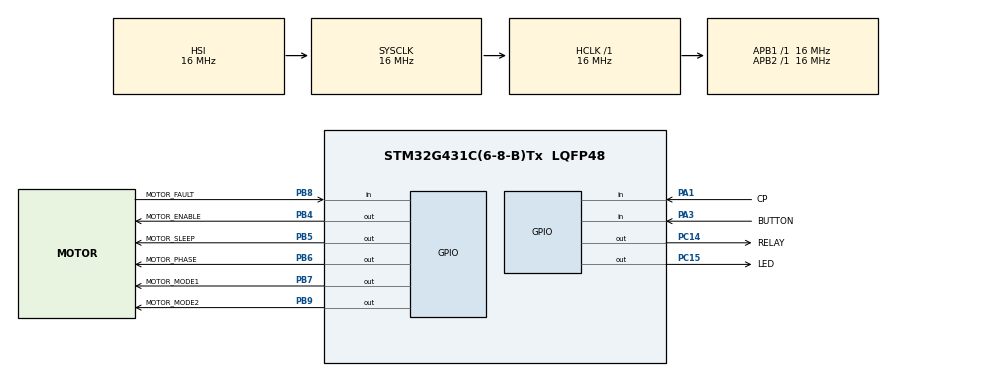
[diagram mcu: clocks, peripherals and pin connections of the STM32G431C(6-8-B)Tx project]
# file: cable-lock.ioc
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Mcu.Family=STM32G4
Mcu.Name=STM32G431C(6-8-B)Tx
Mcu.Package=LQFP48
NVIC.PriorityGroup=NVIC_PRIORITYGROUP_4
PA0.GPIO_Label=CP_WKUP
PA0.Mode=SYS_WakeUp0
PA0.Signal=SYS_WKUP1
PA1.GPIO_Label=CP
PA1.Signal=GPIO_Input
PA13.Mode=Serial_Wire
PA13.Signal=SYS_JTMS-SWDIO
PA14.Mode=Serial_Wire
PA14.Signal=SYS_JTCK-SWCLK
PA2.GPIO_Label=BUTTON_WKUP
PA2.Mode=SYS_WakeUp3
PA2.Signal=SYS_WKUP4
PA3.GPIO_Label=BUTTON
PA3.Signal=GPIO_Input
PB4.GPIO_Label=MOTOR_ENABLE
PB4.Signal=GPIO_Output
PB5.GPIO_Label=MOTOR_SLEEP
PB5.Signal=GPIO_Output
PB6.GPIO_Label=MOTOR_PHASE
PB6.Signal=GPIO_Output
PB7.GPIO_Label=MOTOR_MODE1
PB7.Signal=GPIO_Output
PB8-BOOT0.GPIO_Label=MOTOR_FAULT
PB8-BOOT0.Signal=GPIO_Input
PB9.GPIO_Label=MOTOR_MODE2
PB9.Signal=GPIO_Output
PC14-OSC32_IN.GPIO_Label=RELAY
PC14-OSC32_IN.Signal=GPIO_Output
PC15-OSC32_OUT.GPIO_Label=LED
PC15-OSC32_OUT.Signal=GPIO_Output
ProjectManager.HeapSize=0x200
ProjectManager.StackSize=0x400
ProjectManager.TargetToolchain=Makefile
RCC.AHBFreq_Value=16000000
RCC.APB1Freq_Value=16000000
RCC.APB1TimFreq_Value=16000000
RCC.APB2Freq_Value=16000000
RCC.APB2TimFreq_Value=16000000
RCC.CortexFreq_Value=16000000
RCC.EXTERNAL_CLOCK_VALUE=12288000
RCC.HCLKFreq_Value=16000000
RCC.HSE_VALUE=8000000
RCC.HSI48_VALUE=48000000
RCC.HSI_VALUE=16000000
RCC.LSE_VALUE=32768
RCC.SYSCLKFreq_VALUE=16000000
RCC.USBFreq_Value=64000000
RCC.VCOOutputFreq_Value=128000000
VP_SYS_VS_DBSignals.Mode=DisableDeadBatterySignals
board=custom

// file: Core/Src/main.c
/* USER CODE BEGIN Header */
/**
  ******************************************************************************
  * @file           : main.c
  * @brief          : Main program body
  ******************************************************************************
  * @attention
  *
  * Copyright (c) 2026 STMicroelectronics.
  * All rights reserved.
  *
  * This software is licensed under terms that can be found in the LICENSE file
  * in the root directory of this software component.
  * If no LICENSE file comes with this software, it is provided AS-IS.
  *
  ******************************************************************************
  */
/* USER CODE END Header */
#include "main.h"

/* USER CODE BEGIN Includes */
#include "cable-lock.h"
/* USER CODE END Includes */

void SystemClock_Config(void);
static void MX_GPIO_Init(void);

int main(void)
{

  /* MCU Configuration--------------------------------------------------------*/

  /* Reset of all peripherals, Initializes the Flash interface and the Systick. */
  HAL_Init();

  /* Configure the system clock */
  SystemClock_Config();

  /* Initialize all configured peripherals */
  MX_GPIO_Init();
  /* USER CODE BEGIN 2 */
  cable_lock();
  /* USER CODE END 2 */

  /* Infinite loop */
  while (1)
  {

  }
}

void SystemClock_Config(void)
{
  RCC_OscInitTypeDef RCC_OscInitStruct = {0};
  RCC_ClkInitTypeDef RCC_ClkInitStruct = {0};

  /** Configure the main internal regulator output voltage
  */
  HAL_PWREx_ControlVoltageScaling(PWR_REGULATOR_VOLTAGE_SCALE1);

  /** Initializes the RCC Oscillators according to the specified parameters
  * in the RCC_OscInitTypeDef structure.
  */
  RCC_OscInitStruct.OscillatorType = RCC_OSCILLATORTYPE_HSI;
  RCC_OscInitStruct.HSIState = RCC_HSI_ON;
  RCC_OscInitStruct.HSICalibrationValue = RCC_HSICALIBRATION_DEFAULT;
  RCC_OscInitStruct.PLL.PLLState = RCC_PLL_NONE;
  if (HAL_RCC_OscConfig(&RCC_OscInitStruct) != HAL_OK)
  {
    Error_Handler();
  }

  /** Initializes the CPU, AHB and APB buses clocks
  */
  RCC_ClkInitStruct.ClockType = RCC_CLOCKTYPE_HCLK|RCC_CLOCKTYPE_SYSCLK
                              |RCC_CLOCKTYPE_PCLK1|RCC_CLOCKTYPE_PCLK2;
  RCC_ClkInitStruct.SYSCLKSource = RCC_SYSCLKSOURCE_HSI;
  RCC_ClkInitStruct.AHBCLKDivider = RCC_SYSCLK_DIV1;
  RCC_ClkInitStruct.APB1CLKDivider = RCC_HCLK_DIV1;
  RCC_ClkInitStruct.APB2CLKDivider = RCC_HCLK_DIV1;

  if (HAL_RCC_ClockConfig(&RCC_ClkInitStruct, FLASH_LATENCY_0) != HAL_OK)
  {
    Error_Handler();
  }
}

static void MX_GPIO_Init(void)
{
  GPIO_InitTypeDef GPIO_InitStruct = {0};

  /* GPIO Ports Clock Enable */
  __HAL_RCC_GPIOC_CLK_ENABLE();
  __HAL_RCC_GPIOA_CLK_ENABLE();
  __HAL_RCC_GPIOB_CLK_ENABLE();

  /*Configure GPIO pin Output Level */
  HAL_GPIO_WritePin(GPIOC, RELAY_Pin|LED_Pin, GPIO_PIN_RESET);

  /*Configure GPIO pin Output Level */
  HAL_GPIO_WritePin(GPIOB, MOTOR_ENABLE_Pin|MOTOR_SLEEP_Pin|MOTOR_PHASE_Pin|MOTOR_MODE1_Pin
                          |MOTOR_MODE2_Pin, GPIO_PIN_RESET);

  /*Configure GPIO pins : RELAY_Pin LED_Pin */
  GPIO_InitStruct.Pin = RELAY_Pin|LED_Pin;
  GPIO_InitStruct.Mode = GPIO_MODE_OUTPUT_PP;
  GPIO_InitStruct.Pull = GPIO_NOPULL;
  GPIO_InitStruct.Speed = GPIO_SPEED_FREQ_LOW;
  HAL_GPIO_Init(GPIOC, &GPIO_InitStruct);

  /*Configure GPIO pins : CP_Pin BUTTON_Pin */
  GPIO_InitStruct.Pin = CP_Pin|BUTTON_Pin;
  GPIO_InitStruct.Mode = GPIO_MODE_INPUT;
  GPIO_InitStruct.Pull = GPIO_NOPULL;
  HAL_GPIO_Init(GPIOA, &GPIO_InitStruct);

  /*Configure GPIO pins : MOTOR_ENABLE_Pin MOTOR_SLEEP_Pin MOTOR_PHASE_Pin MOTOR_MODE1_Pin
                           MOTOR_MODE2_Pin */
  GPIO_InitStruct.Pin = MOTOR_ENABLE_Pin|MOTOR_SLEEP_Pin|MOTOR_PHASE_Pin|MOTOR_MODE1_Pin
                          |MOTOR_MODE2_Pin;
  GPIO_InitStruct.Mode = GPIO_MODE_OUTPUT_PP;
  GPIO_InitStruct.Pull = GPIO_NOPULL;
  GPIO_InitStruct.Speed = GPIO_SPEED_FREQ_LOW;
  HAL_GPIO_Init(GPIOB, &GPIO_InitStruct);

  /*Configure GPIO pin : MOTOR_FAULT_Pin */
  GPIO_InitStruct.Pin = MOTOR_FAULT_Pin;
  GPIO_InitStruct.Mode = GPIO_MODE_INPUT;
  GPIO_InitStruct.Pull = GPIO_NOPULL;
  HAL_GPIO_Init(MOTOR_FAULT_GPIO_Port, &GPIO_InitStruct);

}

void Error_Handler(void)
{
  __disable_irq();
  while (1)
  {
  }
}
